# STM32H723 register map
File version: 1.6
CPU: CM7 r0p1, little endian, MPU, FPU, 4 interrupt priority bits
Registers are 32-bit, read-write, reset 0x0 unless marked. A register's access mark holds for its fields unless they carry their own. Offsets are from the block's base; [hi:lo] are bit positions; {n}, {i} and the like mark numbered series; 'fields as' and 'values as' point back to an identical list.

## DBGMCU — Microcontroller Debug Unit
Base 0x5C001000
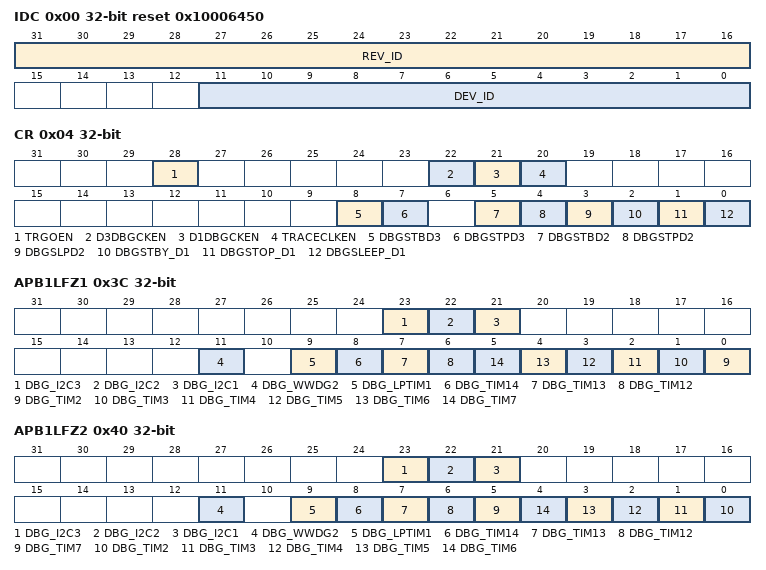
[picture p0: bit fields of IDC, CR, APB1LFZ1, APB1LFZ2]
0x00 IDC ro reset 0x10006450 — DBGMCU Identity Code Register
  [31:16] REV_ID — Revision
  [11:0] DEV_ID — Device ID
0x04 CR — DBGMCU Configuration Register
  [28] TRGOEN — External trigger output enable
  [22] D3DBGCKEN — D3 debug clock enable
  [21] D1DBGCKEN — D1 debug clock enable
  [20] TRACECLKEN — Trace port clock enable
  [8] DBGSTBD3 — Allow debug in D3 Standby mode
  [7] DBGSTPD3 — Allow debug in D3 Stop mode
  [5] DBGSTBD2 — Allow D2 domain debug in Standby mode
  [4] DBGSTPD2 — Allow D2 domain debug in Stop mode
  [3] DBGSLPD2 — Allow D2 domain debug in Sleep mode
  [2] DBGSTBY_D1 — Allow D1 domain debug in Standby mode
  [1] DBGSTOP_D1 — Allow D1 domain debug in Stop mode
  [0] DBGSLEEP_D1 — Allow D1 domain debug in Sleep mode
0x34 APB3FZ1 — DBGMCU APB3 peripheral freeze register CPU1
  [6] WWDG1 — WWDG1 stop in debug
0x38 APB3FZ2 — DBGMCU APB3 peripheral freeze register CPU2
  [6] WWDG1 — WWDG1 stop in debug
0x3C APB1LFZ1 — DBGMCU APB1L peripheral freeze register
  [23] DBG_I2C3 — I2C3 SMBUS timeout stop in debug
  [22] DBG_I2C2 — I2C2 SMBUS timeout stop in debug
  [21] DBG_I2C1 — I2C1 SMBUS timeout stop in debug
  [11] DBG_WWDG2 — WWDG2 stop in debug
  [9] DBG_LPTIM1 — LPTIM1 stop in debug
  [8] DBG_TIM14 — TIM14 stop in debug
  [7] DBG_TIM13 — TIM13 stop in debug
  [6] DBG_TIM12 — TIM12 stop in debug
  [n-2] DBG_TIM{n} (n=2..7) — TIM{n} stop in debug
0x40 APB1LFZ2 — DBGMCU APB1L peripheral freeze register CPU2
  [23] DBG_I2C3 — I2C3 SMBUS timeout stop in debug
  [22] DBG_I2C2 — I2C2 SMBUS timeout stop in debug
  [21] DBG_I2C1 — I2C1 SMBUS timeout stop in debug
  [11] DBG_WWDG2 — WWDG2 stop in debug
  [9] DBG_LPTIM1 — LPTIM1 stop in debug
  [8] DBG_TIM14 — TIM14 stop in debug
  [7] DBG_TIM13 — TIM13 stop in debug
  [6] DBG_TIM12 — TIM12 stop in debug
  [5] DBG_TIM7 — TIM4 stop in debug
  [n-2] DBG_TIM{n} (n=2..6) — TIM{n} stop in debug
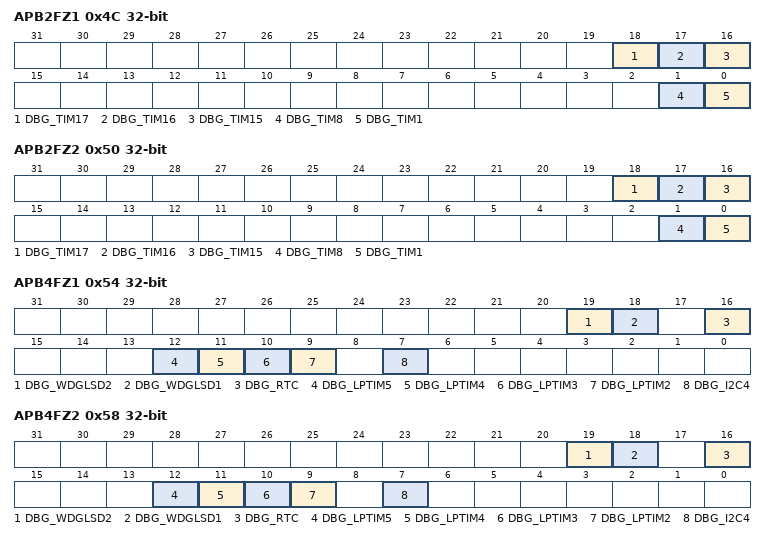
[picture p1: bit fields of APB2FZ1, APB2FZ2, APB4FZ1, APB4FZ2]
0x4C APB2FZ1 — DBGMCU APB2 peripheral freeze register
  [18] DBG_TIM17 — TIM17 stop in debug
  [17] DBG_TIM16 — TIM16 stop in debug
  [16] DBG_TIM15 — TIM15 stop in debug
  [1] DBG_TIM8 — TIM8 stop in debug
  [0] DBG_TIM1 — TIM1 stop in debug
0x50 APB2FZ2 — DBGMCU APB2 peripheral freeze register CPU2
  fields as APB2FZ1
0x54 APB4FZ1 — DBGMCU APB4 peripheral freeze register
  [19] DBG_WDGLSD2 — Independent watchdog for D2 stop in debug
  [18] DBG_WDGLSD1 — Independent watchdog for D1 stop in debug
  [16] DBG_RTC — RTC stop in debug
  [12] DBG_LPTIM5 — LPTIM5 stop in debug
  [11] DBG_LPTIM4 — LPTIM4 stop in debug
  [10] DBG_LPTIM3 — LPTIM2 stop in debug
  [9] DBG_LPTIM2 — LPTIM2 stop in debug
  [7] DBG_I2C4 — I2C4 SMBUS timeout stop in debug
0x58 APB4FZ2 — DBGMCU APB4 peripheral freeze register CPU2
  [19] DBG_WDGLSD2 — LS watchdog for D2 stop in debug
  [18] DBG_WDGLSD1 — LS watchdog for D1 stop in debug
  [16] DBG_RTC — RTC stop in debug
  [12] DBG_LPTIM5 — LPTIM5 stop in debug
  [11] DBG_LPTIM4 — LPTIM4 stop in debug
  [10] DBG_LPTIM3 — LPTIM2 stop in debug
  [9] DBG_LPTIM2 — LPTIM2 stop in debug
  [7] DBG_I2C4 — I2C4 SMBUS timeout stop in debug

## DELAY_Block_SDMMC1
Base 0x52008000
Same registers: DELAY_Block_SDMMC2 0x48022800, Delay_Block_OCTOSPI1 0x52006000, Delay_Block_OCTOSPI2 0x5200B000
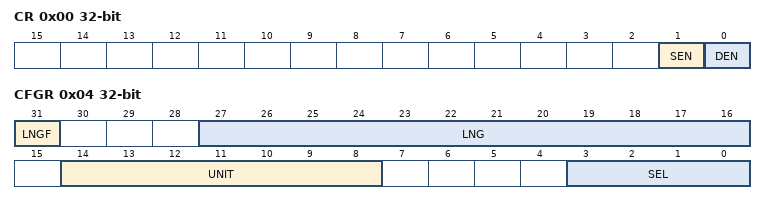
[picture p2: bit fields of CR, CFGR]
0x00 CR — DLYB control register
  [1] SEN — Sampler length enable bit
  [0] DEN — Delay block enable bit
0x04 CFGR — DLYB configuration register
  [31] LNGF — Length valid flag
  [27:16] LNG — Delay line length value
  [14:8] UNIT — Delay Defines the delay of a Unit delay cell
  [3:0] SEL — Select the phase for the Output clock

## Ethernet_MTL
Base 0x40028C00
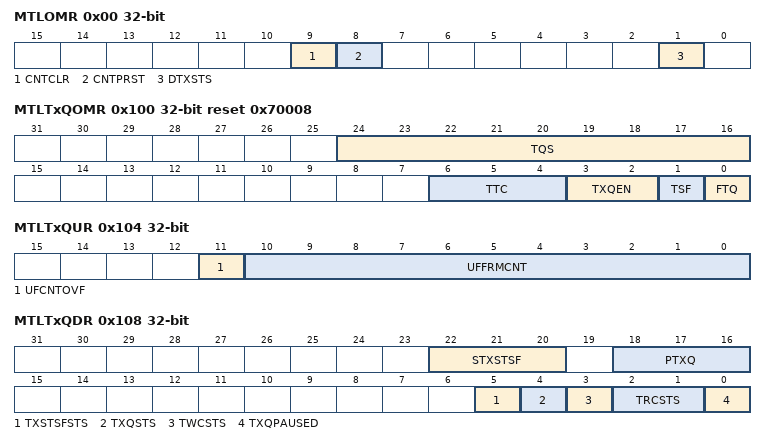
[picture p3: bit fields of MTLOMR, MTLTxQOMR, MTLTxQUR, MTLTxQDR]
0x00 MTLOMR access not given — Operating mode Register
  [9] CNTCLR — Counters Reset
  [8] CNTPRST — Counters Preset
  [1] DTXSTS — Drop Transmit Status
0x20 MTLISR access not given — Interrupt status Register
  [0] Q0IS — Queue interrupt status
0x100 MTLTxQOMR access not given reset 0x70008 — Tx queue operating mode Register
  [24:16] TQS — Transmit Queue Size
  [6:4] TTC — Transmit Threshold Control
  [3:2] TXQEN — Transmit Queue Enable
  [1] TSF — Transmit Store and Forward
  [0] FTQ — Flush Transmit Queue
0x104 MTLTxQUR access not given — Tx queue underflow register
  [11] UFCNTOVF — Overflow Bit for Underflow Packet Counter
  [10:0] UFFRMCNT — Underflow Packet Counter
0x108 MTLTxQDR access not given — Tx queue debug Register
  [22:20] STXSTSF — Number of Status Words in Tx Status FIFO of Queue
  [18:16] PTXQ — Number of Packets in the Transmit Queue
  [5] TXSTSFSTS — MTL Tx Status FIFO Full Status
  [4] TXQSTS — MTL Tx Queue Not Empty Status
  [3] TWCSTS — MTL Tx Queue Write Controller Status
  [2:1] TRCSTS — MTL Tx Queue Read Controller Status
  [0] TXQPAUSED — Transmit Queue in Pause
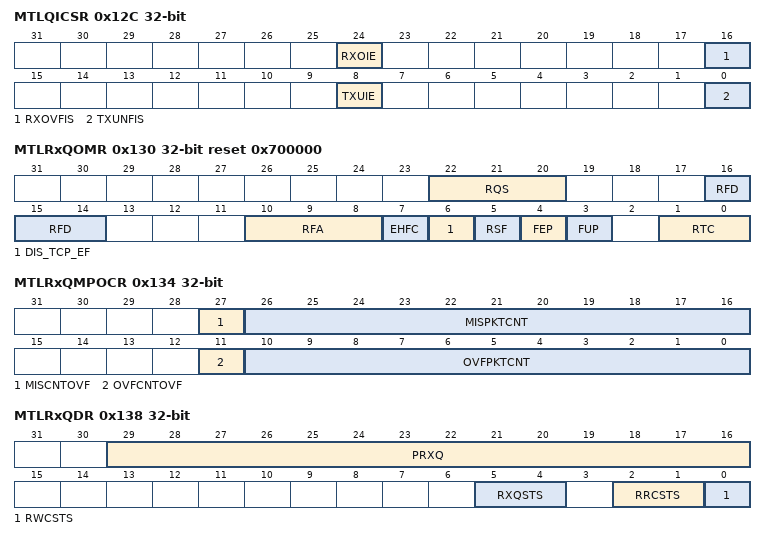
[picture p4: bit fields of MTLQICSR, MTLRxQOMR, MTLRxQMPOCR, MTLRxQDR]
0x12C MTLQICSR access not given — Queue interrupt control status Register
  [24] RXOIE — Receive Queue Overflow Interrupt Enable
  [16] RXOVFIS — Receive Queue Overflow Interrupt Status
  [8] TXUIE — Transmit Queue Underflow Interrupt Enable
  [0] TXUNFIS — Transmit Queue Underflow Interrupt Status
0x130 MTLRxQOMR access not given reset 0x700000 — Rx queue operating mode register
  [22:20] RQS — Receive Queue Size
  [16:14] RFD — Threshold for Deactivating Flow Control
  [10:8] RFA — Threshold for Activating Flow Control
  [7] EHFC — Enable Hardware Flow Control
  [6] DIS_TCP_EF — Disable Dropping of TCP
  [5] RSF — Receive Queue Store and Forward
  [4] FEP — Forward Error Packets
  [3] FUP — Forward Undersized Good Packets
  [1:0] RTC — Receive Queue Threshold Control
0x134 MTLRxQMPOCR access not given — Rx queue missed packet and overflow counter register
  [27] MISCNTOVF — Missed Packet Counter Overflow Bit
  [26:16] MISPKTCNT — Missed Packet Counter
  [11] OVFCNTOVF — Overflow Counter Overflow Bit
  [10:0] OVFPKTCNT — Overflow Packet Counter
0x138 MTLRxQDR access not given — Rx queue debug register
  [29:16] PRXQ — Number of Packets in Receive Queue
  [5:4] RXQSTS — MTL Rx Queue Fill-Level Status
  [2:1] RRCSTS — MTL Rx Queue Read Controller State
  [0] RWCSTS — MTL Rx Queue Write Controller Active Status
